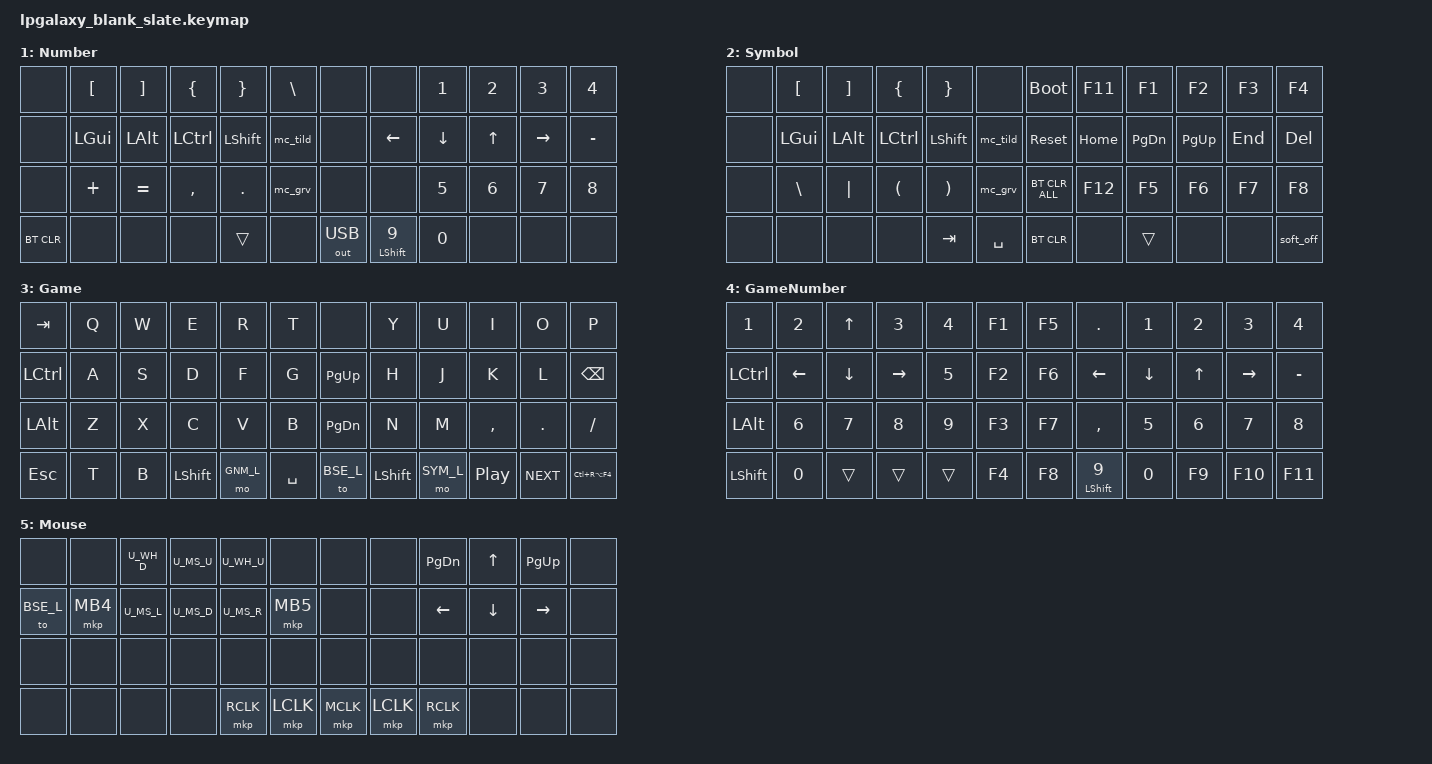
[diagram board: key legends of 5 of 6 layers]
/*
 * Copyright (c) 2023 Marcel Keßler
 *
 * SPDX-License-Identifier: MIT
 */

#include <behaviors.dtsi>
#include <dt-bindings/zmk/keys.h>
#include <dt-bindings/zmk/bt.h>
#include <dt-bindings/zmk/outputs.h>
#include "mouse.dtsi"

// Shortcuts
#define XXX &none
#define ___ &trans
#define BT(n) BT_SEL n

// Layers
#define BSE_L 0
#define NUM_L 1
#define SYM_L 2
#define GME_L 3
#define GNM_L 4
#define MSE_L 5

// Config
&lt { quick_tap_ms = <100>; tapping-term-ms = <150>; };

&caps_word {
    continue-list = <UNDERSCORE MINUS SPACE>;
};

// Keymap
/ {
    chosen {
        zmk,physical-layout = &layout_ortho_4x12_all1u;
    };

    behaviors {
        ltp: layer_tap_preferred {
            compatible = "zmk,behavior-hold-tap";
            label = "LAYER_TAP_PREFERRED";
            #binding-cells = <2>;
            tapping-term-ms = <200>;
            quick-tap-ms = <0>;
            flavor = "tap-preferred";
            bindings = <&mo>, <&mc_dead>;
        };
        mtp: mod_tap_preferred {
            compatible = "zmk,behavior-hold-tap";
            label = "MOD_TAP_PREFERRED";
            #binding-cells = <2>;
            tapping-term-ms = <200>;
            quick-tap-ms = <0>;
            flavor = "tap-preferred";
            bindings = <&kp>, <&kp>;
        };
        mtm: mod_tap_mouse {
            compatible = "zmk,behavior-hold-tap";
            label = "MOD_TAP_MOUSE";
            #binding-cells = <2>;
            tapping-term-ms = <200>;
            quick-tap-ms = <0>;
            flavor = "tap-preferred";
            bindings = <&kp>, <&to>;
        };
        bht: balanced_hold_tap {
            compatible = "zmk,behavior-hold-tap";
            label = "BALANCED_HOLD_TAP";
            #binding-cells = <2>;
            tapping-term-ms = <150>;
            quick-tap-ms = <0>;
            bindings = <&mo>, <&kp>;
        };
    };

    macros {
        mc_dead: mc_dead {
            label = "mc_dead";
            compatible = "zmk,behavior-macro";
            #binding-cells = <0>;
            wait-ms = <5>;
            tap-ms = <10>;
            bindings
                = <&macro_press &kp LSHIFT>
                , <&macro_tap &kp QUOT>
                , <&macro_release &kp LSHIFT>
            ;
        };
        mc_quot: mc_quote {
            label = "mc_quot";
            compatible = "zmk,behavior-macro";
            #binding-cells = <0>;
            bindings
                = <&macro_tap &kp QUOT>
                , <&macro_tap &kp SPACE>
            ;
        };
        mc_dqt: mc_dqt {
            label = "mc_dqt";
            compatible = "zmk,behavior-macro";
            #binding-cells = <0>;
            bindings
                = <&macro_press &kp LSHIFT>
                , <&macro_tap &kp QUOT>
                , <&macro_release &kp LSHIFT>
                , <&macro_tap &kp SPACE>
            ;
        };
        mc_grv: mc_grave {
            label = "mc_grv";
            compatible = "zmk,behavior-macro";
            #binding-cells = <0>;
            bindings
                = <&macro_tap &kp GRAVE>
                , <&macro_tap &kp SPACE>
            ;
        };
        mc_tild: mc_tilde {
            label = "mc_tild";
            compatible = "zmk,behavior-macro";
            #binding-cells = <0>;
            bindings
                = <&macro_press &kp LSHIFT>
                , <&macro_tap &kp GRAVE>
                , <&macro_release &kp LSHIFT>
                , <&macro_tap &kp SPACE>
            ;
        };
    };

    combos {
           compatible = "zmk,combos";
           combo_esc {
                timeout-ms = <35>;
                key-positions = <15 16>;
                bindings = <&kp ESC>;
                layers = <0 1 2>;
           };
           combo_ret {
                timeout-ms = <35>;
                key-positions = <20 21>;
                bindings = <&kp RET>;
                layers = <0 1 2 3 4>;
           };
           combo_quote {
                timeout-ms = <35>;
                key-positions = <26 27>;
                bindings = <&mc_quot>;
                layers = <0>;
           };
           combo_dqt {
             timeout-ms = <35>;
             key-positions = <27 28>;
             bindings = <&mc_dqt>;
             layers = <0>;
           };
            combo_colon {
                timeout-ms = <35>;
                key-positions = <32 33>;
                bindings = <&kp COLON>;
                layers = <0 1 2>;
            };
            combo_semi {
                timeout-ms = <35>;
                key-positions = <33 34>;
                bindings = <&kp SEMI>;
                layers = <0 1 2>;
            };
    };
    
    tap_dances {
        shifty: shift_caps_word {
        compatible = "zmk,behavior-tap-dance";
        label = "TD_SHIFTY";
        #binding-cells = <0>;
        tapping-term-ms = <150>;
        bindings = <&kp LSHFT>, <&caps_word>;
        };
    };

    keymap {
        compatible = "zmk,keymap";

        bse_layer {
            label = "Based";
            bindings = <
            &kp TAB          &kp Q          &kp W      &kp E       &kp R          &kp T               &to GME_L      &kp Y       &kp U            &kp I       &kp O      &kp P
            &mtm LCTRL MSE_L &kp A          &kp S      &kp D       &kp F          &kp G               &none          &kp H       &kp J            &kp K       &kp L      &kp BKSP
            &kp LALT         &mtp LCTRL Z   &kp X      &kp C       &kp V          &kp B               &none          &kp N       &kp M            &kp COMMA   &kp DOT    &mtp LALT FSLH
            &kp ESC          &bt BT(0)      &bt BT(1)  &bt BT(2)   &mo NUM_L      &mtp LGUI SPACE     &out OUT_BLE   &shifty     &ltp SYM_L &none &bt BT(3)   &bt BT(4)  &kp RET   
            >;
        };

        num_layer {
            label = "Number";
            bindings = <
            &none      &kp LBKT         &kp RBKT     &kp LBRC     &kp RBRC    &kp BSLH     &none        &none          &kp N1         &kp N2       &kp N3       &kp N4
            &none      &kp LGUI         &kp LALT     &kp LCTRL    &kp LSHIFT  &mc_tild     &none        &kp LEFT       &kp DOWN       &kp UP       &kp RIGHT    &kp MINUS
            &none      &kp PLUS         &kp EQUAL    &kp COMMA    &kp DOT     &mc_grv      &none        &none          &kp N5         &kp N6       &kp N7       &kp N8
            &bt BT_CLR &none            &none        &none        &trans      &none        &out OUT_USB &mt LSHIFT N9  &kp N0         &none        &none        &none
            >;
        };

        sym_layer {
            label = "Symbol";
            bindings = <
            &none           &kp LBKT   &kp RBKT   &kp LBRC   &kp RBRC    &none            &bootloader     &kp F11        &kp F1       &kp F2       &kp F3         &kp F4
            &none           &kp LGUI   &kp LALT   &kp LCTRL  &kp LSHIFT  &mc_tild         &sys_reset      &kp HOME       &kp PG_DN    &kp PG_UP    &kp END        &kp DELETE
            &none           &kp BSLH   &kp PIPE   &kp LPRN   &kp RPRN    &mc_grv          &bt BT_CLR_ALL  &kp F12        &kp F5       &kp F6       &kp F7         &kp F8
            &none           &none      &none      &none      &kp TAB     &kp SPACE        &bt BT_CLR      &none          &trans       &none        &none          &soft_off
            >;
        };

        gme_layer {
            label = "Game";
            bindings = <
            &kp TAB    &kp Q      &kp W      &kp E       &kp R          &kp T       &none        &kp Y        &kp U          &kp I       &kp O      &kp P
            &kp LCTRL  &kp A      &kp S      &kp D       &kp F          &kp G       &kp PG_UP    &kp H        &kp J          &kp K       &kp L      &kp BKSP
            &kp LALT   &kp Z      &kp X      &kp C       &kp V          &kp B       &kp PG_DN    &kp N        &kp M          &kp COMMA   &kp DOT    &kp FSLH
            &kp ESC    &kp T      &kp B      &kp LSHIFT  &mo GNM_L      &kp SPACE   &to BSE_L    &kp LSHIFT   &mo SYM_L      &kp C_PP    &kp C_NEXT &kp LC(RA(F4))
            >;
        };

        gnm_layer {
            label = "GameNumber";
            bindings = <
            &kp N1     &kp N2     &kp UP     &kp N3      &kp N4      &kp F1  &kp F5    &kp DOT        &kp N1         &kp N2       &kp N3     &kp N4
            &kp LCTL   &kp LEFT   &kp DOWN   &kp RIGHT   &kp N5      &kp F2  &kp F6    &kp LEFT       &kp DOWN       &kp UP       &kp RIGHT  &kp MINUS
            &kp LALT   &kp N6     &kp N7     &kp N8      &kp N9      &kp F3  &kp F7    &kp COMMA      &kp N5         &kp N6       &kp N7     &kp N8
            &kp LSHIFT &kp N0     &trans     &trans      &trans      &kp F4  &kp F8    &mt LSHIFT N9  &kp N0         &kp F9       &kp F10    &kp F11
            >;
        };

        mouse_layer {
            label = "Mouse";
            bindings = <
            &none       &none            U_WH_D       U_MS_U       U_WH_U      &none        &none      &none          &kp PG_DN      &kp UP       &kp PG_UP    &none
            &to BSE_L   &mkp MB4         U_MS_L       U_MS_D       U_MS_R      &mkp MB5     &none      &none          &kp LEFT       &kp DOWN     &kp RIGHT    &none
            &none       &none            &none        &none        &none       &none        &none      &none          &none          &none        &none        &none
            &none       &none            &none        &none        &mkp RCLK   &mkp LCLK    &mkp MCLK  &mkp LCLK      &mkp RCLK      &none        &none        &none
            >;
        };
    };
};

